# STM32F215 register map
File version: 1.1
CPU: CM3 r1p1, little endian, no MPU, no FPU, 4 interrupt priority bits
Registers are 32-bit, read-write, reset 0x0 unless marked. A register's access mark holds for its fields unless they carry their own. Offsets are from the block's base; [hi:lo] are bit positions; {n}, {i} and the like mark numbered series.

## SYSCFG — System configuration controller
Base 0x40013800
0x00 MEMRM — memory remap register
  [1:0] MEM_MODE
0x04 PMC — peripheral mode configuration register
  [23] MII_RMII_SEL — Ethernet PHY interface selection
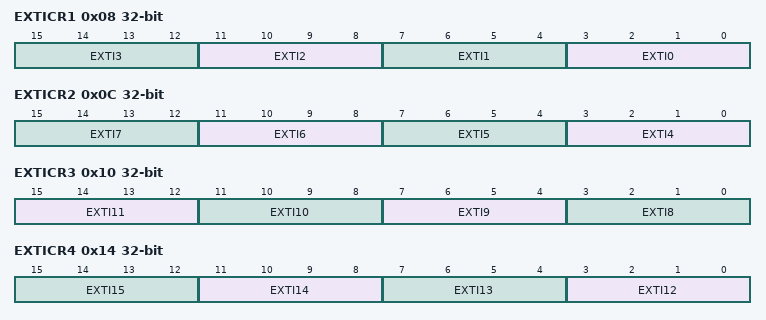
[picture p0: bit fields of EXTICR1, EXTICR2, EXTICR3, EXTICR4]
0x08 EXTICR1 — external interrupt configuration register 1
  [4n+3:4n] EXTI{n} (n=0..3) — EXTI x configuration (x = 0 to 3)
0x0C EXTICR2 — external interrupt configuration register 2
  [4n-13:4n-16] EXTI{n} (n=4..7) — EXTI x configuration (x = 4 to 7)
0x10 EXTICR3 — external interrupt configuration register 3
  [15:12] EXTI11 — EXTI x configuration (x = 8 to 11)
  [11:8] EXTI10
  [7:4] EXTI9 — EXTI x configuration (x = 8 to 11)
  [3:0] EXTI8 — EXTI x configuration (x = 8 to 11)
0x14 EXTICR4 — external interrupt configuration register 4
  [4n-45:4n-48] EXTI{n} (n=12..15) — EXTI x configuration (x = 12 to 15)
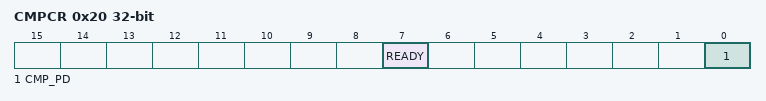
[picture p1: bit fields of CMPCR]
0x20 CMPCR access per field — Compensation cell control register
  [7] READY ro
  [0] CMP_PD rw — Compensation cell power-down

## PWR — Power control
Base 0x40007000
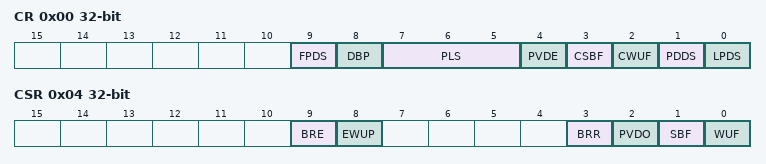
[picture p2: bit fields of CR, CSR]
0x00 CR — power control register
  [9] FPDS — Flash power down in Stop mode
  [8] DBP — Disable backup domain write protection
  [7:5] PLS — PVD level selection
  [4] PVDE — Power voltage detector enable
  [3] CSBF — Clear standby flag
  [2] CWUF — Clear wakeup flag
  [1] PDDS — Power down deepsleep
    0=STOP_MODE (Enter Stop mode when the CPU enters deepsleep); 1=STANDBY_MODE (Enter Standby mode when the CPU enters deepsleep)
  [0] LPDS — Low-power deep sleep
0x04 CSR access per field — power control/status register
  [9] BRE rw — Backup regulator enable
  [8] EWUP rw — Enable WKUP pin
  [3] BRR ro — Backup regulator ready
  [2] PVDO ro — PVD output
  [1] SBF ro — Standby flag
  [0] WUF ro — Wakeup flag

## IWDG — Independent watchdog
Base 0x40003000
0x00 KR 16-bit wo — Key register
  [15:0] KEY — Key value (write only, read 0000h)
    0x5555=Unlock (Enable access to PR, RLR and WINR registers); 0xAAAA=Feed watchdog with RLR register value; 0xCCCC=Start the watchdog
0x04 PR 16-bit — Prescaler register
  [2:0] PR — Prescaler divider
    0=DivideBy4 (Divider /4); 1=DivideBy8 (Divider /8); 2=DivideBy16 (Divider /16); 3=DivideBy32 (Divider /32); 4=DivideBy64 (Divider /64); 5=DivideBy128 (Divider /128); other=DivideBy256 (Divider /256)
0x08 RLR 16-bit reset 0xFFF — Reload register
  [11:0] RL — Watchdog counter reload value
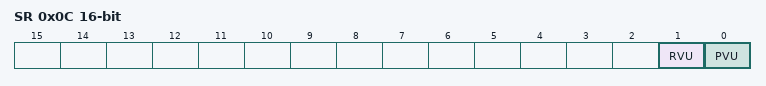
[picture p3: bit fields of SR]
0x0C SR 16-bit ro — Status register
  [1] RVU — Watchdog counter reload value update
  [0] PVU — Watchdog prescaler value update

## WWDG — Window watchdog
Base 0x40002C00
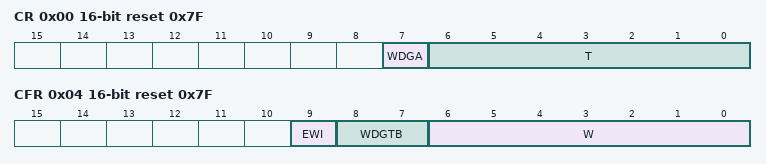
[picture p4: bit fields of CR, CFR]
0x00 CR 16-bit reset 0x7F — Control register
  [7] WDGA — Activation bit
    0=Disabled (Watchdog disabled); 1=Enabled (Watchdog enabled)
  [6:0] T — 7-bit counter (MSB to LSB)
0x04 CFR 16-bit reset 0x7F — Configuration register
  [9] EWI — Early wakeup interrupt
    on write: 1=Enable (interrupt occurs whenever the counter reaches the value 0x40)
  [8:7] WDGTB — Timer base
    0=Div1 (Counter clock (PCLK1 div 4096) div 1); 1=Div2 (Counter clock (PCLK1 div 4096) div 2); 2=Div4 (Counter clock (PCLK1 div 4096) div 4); 3=Div8 (Counter clock (PCLK1 div 4096) div 8)
  [6:0] W — 7-bit window value
0x08 SR 16-bit — Status register
  [0] EWIF write-0-clears — Early wakeup interrupt flag
    on read: 0=Finished (The EWI Interrupt Service Routine has been serviced); 1=Pending (The EWI Interrupt Service Routine has been triggered) | on write: 0=Finished (The EWI Interrupt Service Routine has been serviced)

## TIM6 — Basic-timers
Base 0x40001000
Same registers: TIM7 0x40001400
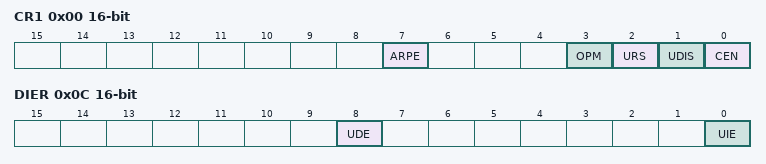
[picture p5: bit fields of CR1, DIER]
0x00 CR1 16-bit — control register 1
  [7] ARPE — Auto-reload preload enable
    0=Disabled (TIMx_APRR register is not buffered); 1=Enabled (TIMx_APRR register is buffered)
  [3] OPM — One-pulse mode
    0=Disabled (Counter is not stopped at update event); 1=Enabled (Counter stops counting at the next update event (clearing the CEN bit))
  [2] URS — Update request source
    0=AnyEvent (Any of counter overflow/underflow, setting UG, or update through slave mode, generates an update interrupt or DMA request); 1=CounterOnly (Only counter overflow/underflow generates an update interrupt or DMA request)
  [1] UDIS — Update disable
    0=Enabled (Update event enabled); 1=Disabled (Update event disabled)
  [0] CEN — Counter enable
    0=Disabled (Counter disabled); 1=Enabled (Counter enabled)
0x04 CR2 16-bit — control register 2
  [6:4] MMS — Master mode selection
    0=Reset (Use UG bit from TIMx_EGR register); 1=Enable (Use CNT bit from TIMx_CEN register); 2=Update (Use the update event)
0x0C DIER 16-bit — DMA/Interrupt enable register
  [8] UDE — Update DMA request enable
    0=Disabled (Update DMA request disabled); 1=Enabled (Update DMA request enabled)
  [0] UIE — Update interrupt enable
    0=Disabled (Update interrupt disabled); 1=Enabled (Update interrupt enabled)
0x10 SR 16-bit — status register
  [0] UIF write-0-clears — Update interrupt flag
    on read: 0=NoUpdateOccurred; 1=UpdatePending (Update interrupt pending) | on write: 0=Clear flag
0x14 EGR 16-bit wo — event generation register
  [0] UG — Update generation
    1=Update (Re-initializes the timer counter and generates an update of the registers.)
0x24 CNT 16-bit — counter
  [15:0] CNT — Low counter value
0x28 PSC 16-bit — prescaler
  [15:0] PSC — Prescaler value
0x2C ARR 16-bit reset 0xFFFF — auto-reload register
  [15:0] ARR — Low Auto-reload value
